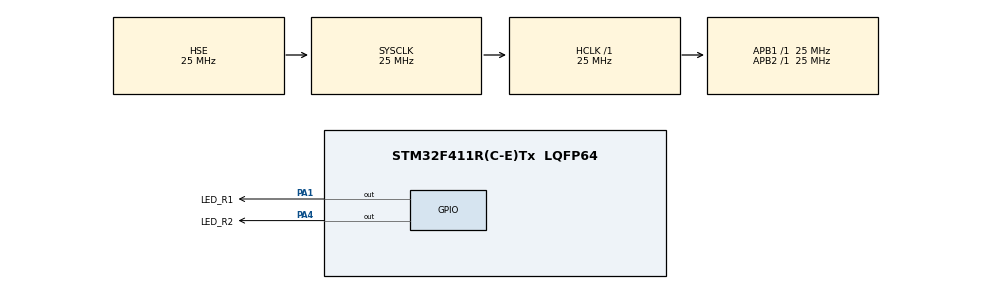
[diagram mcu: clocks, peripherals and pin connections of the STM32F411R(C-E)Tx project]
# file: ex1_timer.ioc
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Mcu.Family=STM32F4
Mcu.Name=STM32F411R(C-E)Tx
Mcu.Package=LQFP64
NVIC.PriorityGroup=NVIC_PRIORITYGROUP_4
NVIC.TIM3_IRQn=true\:0\:0\:false\:false\:true\:true\:true\:true
PA1.GPIO_Label=LED_R1
PA1.GPIO_ModeDefaultOutputPP=GPIO_MODE_OUTPUT_PP
PA1.GPIO_PuPd=GPIO_NOPULL
PA1.GPIO_Speed=GPIO_SPEED_FREQ_VERY_HIGH
PA1.PinState=GPIO_PIN_RESET
PA1.Signal=GPIO_Output
PA13.Mode=Serial_Wire
PA13.Signal=SYS_JTMS-SWDIO
PA14.Mode=Serial_Wire
PA14.Signal=SYS_JTCK-SWCLK
PA4.GPIO_Label=LED_R2
PA4.GPIO_ModeDefaultOutputPP=GPIO_MODE_OUTPUT_PP
PA4.GPIO_PuPd=GPIO_NOPULL
PA4.GPIO_Speed=GPIO_SPEED_FREQ_VERY_HIGH
PA4.PinState=GPIO_PIN_RESET
PA4.Signal=GPIO_Output
PH0\ -\ OSC_IN.Mode=HSE-External-Oscillator
PH0\ -\ OSC_IN.Signal=RCC_OSC_IN
PH1\ -\ OSC_OUT.Mode=HSE-External-Oscillator
PH1\ -\ OSC_OUT.Signal=RCC_OSC_OUT
ProjectManager.HeapSize=0x200
ProjectManager.StackSize=0x400
ProjectManager.TargetToolchain=STM32CubeIDE
RCC.AHBFreq_Value=25000000
RCC.APB1Freq_Value=25000000
RCC.APB1TimFreq_Value=25000000
RCC.APB2Freq_Value=25000000
RCC.APB2TimFreq_Value=25000000
RCC.CortexFreq_Value=25000000
RCC.HCLKFreq_Value=25000000
RCC.HSE_VALUE=25000000
RCC.HSI_VALUE=16000000
RCC.LSE_VALUE=32768
RCC.SYSCLKFreq_VALUE=25000000
RCC.SYSCLKSource=RCC_SYSCLKSOURCE_HSE
RCC.VCOOutputFreq_Value=192000000
TIM3.Period=49999
TIM3.Prescaler=249
TIM4.Prescaler=24999
VP_TIM3_VS_ClockSourceINT.Mode=Internal
VP_TIM4_VS_ClockSourceINT.Mode=Internal
board=custom

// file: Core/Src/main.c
/* USER CODE BEGIN Header */
/**
  ******************************************************************************
  * @file           : main.c
  * @brief          : Main program body
  ******************************************************************************
  * @attention
  *
  * Copyright (c) 2025 STMicroelectronics.
  * All rights reserved.
  *
  * This software is licensed under terms that can be found in the LICENSE file
  * in the root directory of this software component.
  * If no LICENSE file comes with this software, it is provided AS-IS.
  *
  ******************************************************************************
  */
/* USER CODE END Header */
#include "main.h"
#include "tim.h"
#include "gpio.h"

void SystemClock_Config(void);

/* USER CODE BEGIN 0 */
void HAL_TIM_PeriodElapsedCallback(TIM_HandleTypeDef * htim){
	if(htim->Instance == TIM3){
		HAL_GPIO_TogglePin(LED_R2_GPIO_Port, LED_R2_Pin);
	}
}
/* USER CODE END 0 */

int main(void)
{

  /* MCU Configuration--------------------------------------------------------*/

  /* Reset of all peripherals, Initializes the Flash interface and the Systick. */
  HAL_Init();

  /* Configure the system clock */
  SystemClock_Config();

  /* Initialize all configured peripherals */
  MX_GPIO_Init();
  MX_TIM3_Init();
  MX_TIM4_Init();
  /* USER CODE BEGIN 2 */
  HAL_TIM_Base_Start(&htim4);
  HAL_TIM_Base_Start(&htim3);
  /* USER CODE END 2 */

  /* Infinite loop */
  /* USER CODE BEGIN WHILE */
  while (1)
  {
	  if(__HAL_TIM_GET_COUNTER(&htim4) >= 250){
		  HAL_GPIO_TogglePin(LED_R1_GPIO_Port, LED_R1_Pin);
		  __HAL_TIM_SET_COUNTER(&htim4, 0);
	  }
    /* USER CODE END WHILE */

  }
}

void SystemClock_Config(void)
{
  RCC_OscInitTypeDef RCC_OscInitStruct = {0};
  RCC_ClkInitTypeDef RCC_ClkInitStruct = {0};

  /** Configure the main internal regulator output voltage
  */
  __HAL_RCC_PWR_CLK_ENABLE();
  __HAL_PWR_VOLTAGESCALING_CONFIG(PWR_REGULATOR_VOLTAGE_SCALE1);

  /** Initializes the RCC Oscillators according to the specified parameters
  * in the RCC_OscInitTypeDef structure.
  */
  RCC_OscInitStruct.OscillatorType = RCC_OSCILLATORTYPE_HSE;
  RCC_OscInitStruct.HSEState = RCC_HSE_ON;
  RCC_OscInitStruct.PLL.PLLState = RCC_PLL_NONE;
  if (HAL_RCC_OscConfig(&RCC_OscInitStruct) != HAL_OK)
  {
    Error_Handler();
  }

  /** Initializes the CPU, AHB and APB buses clocks
  */
  RCC_ClkInitStruct.ClockType = RCC_CLOCKTYPE_HCLK|RCC_CLOCKTYPE_SYSCLK
                              |RCC_CLOCKTYPE_PCLK1|RCC_CLOCKTYPE_PCLK2;
  RCC_ClkInitStruct.SYSCLKSource = RCC_SYSCLKSOURCE_HSE;
  RCC_ClkInitStruct.AHBCLKDivider = RCC_SYSCLK_DIV1;
  RCC_ClkInitStruct.APB1CLKDivider = RCC_HCLK_DIV1;
  RCC_ClkInitStruct.APB2CLKDivider = RCC_HCLK_DIV1;

  if (HAL_RCC_ClockConfig(&RCC_ClkInitStruct, FLASH_LATENCY_0) != HAL_OK)
  {
    Error_Handler();
  }
}

void Error_Handler(void)
{
  __disable_irq();
  while (1)
  {
  }
}
